LIN_description_file;
LIN_protocol_version = "2.1";
LIN_language_version = "2.1";
LIN_speed = 19.2 kbps;

Nodes {
  Master: BCM, 10 ms, 0.1 ms ;
  Slave: DHL, HFA, LIN尾燈, PWM, RLN, RLS, CEM, RLN ;
}

Signals {
  WiprReq: 3, 10, RLS, BCM ;
  PosnLightReq: 1, 0, RLS, BCM ;
  LowBeamReq: 1, 0, RLS, BCM ;
  RLS_RespErr: 1, 0, RLS, BCM ;
  LightSnsrFailSts: 1, 0, RLS, BCM ;
  RainSnsrFailSts: 1, 0, RLS, BCM ;
  TempFailSts: 1, 0, RLS, BCM ;
  InitnFailSts: 1, 0, RLS, BCM ;
  VoltFailSts: 1, 0, RLS, BCM ;
  CloseSRReq: 1, 0, RLS, BCM ;
  VehTypFailrSts: 1, 0, RLS, BCM ;
  DHL_DoorHndlReq: 2, 0, DHL, BCM ;
  DHL_LockSnsrErr: 1, 0, DHL, BCM ;
  DHL_UnlockSnsrErr: 1, 0, DHL, BCM ;
  HFA_OperReq: 2, 0, HFA, BCM ;
  HFA_RespErr: 2, 0, HFA, BCM ;
  HFA_HWErr: 1, 0, HFA, BCM ;
  CentralCtrlLockSwtErrSts: 1, 0, PWM, BCM ;
  PowerCutSwtErrSts: 1, 0, PWM, BCM ;
  CentralCtrlLockSwt: 1, 0, PWM, BCM ;
  PowerCutSwt: 1, 0, PWM, BCM ;
  MirrFoldSwt: 1, 0, PWM, BCM ;
  MirrFold_LSeldSwtErrSts: 1, 0, PWM, BCM ;
  MirrFold_RSeldSwtErrSts: 1, 0, PWM, BCM ;
  Mirr_Swt_Cmd: 4, 0, PWM, BCM ;
  Mirr_Swt_CmdErrSts: 1, 0, PWM, BCM ;
  RFLBrkLmpSts: 1, 0, LIN尾燈, CEM ;
  LBrkLmpFailSts_RLN: 1, 0, RLN, BCM ;
  RBrkLmpFailSts_RLN: 1, 0, RLN, BCM ;
  HiPosnBrkBeamFailSts_RLN: 1, 0, RLN, BCM ;
  LPosnBeamFailSts_RLN: 1, 0, RLN, BCM ;
  RPosnBeamFailSts_RLN: 1, 0, RLN, BCM ;
  LTurnBeamFailSts_RLN: 1, 0, RLN, BCM ;
  RTurnBeamFailSts_RLN: 1, 0, RLN, BCM ;
  LRvrsBeamFailSts_RLN: 1, 0, RLN, BCM ;
  RRvrsBeamFailSts_RLN: 1, 0, RLN, BCM ;
  RTurnLmpWorkCmd_RLN: 1, 0, BCM, RLN ;
  LTurnLmpWorkCmd_RLN: 1, 0, BCM, RLN ;
  RRPosnLmpWorkCmd_RLN: 1, 0, BCM, RLN ;
  LRPosnLmpWorkCmd_RLN: 1, 0, BCM, RLN ;
  ReversLampWorkCmd_RLN: 1, 0, BCM, RLN ;
  BrkLmpWorkCmd_RLN: 1, 0, BCM, RLN ;
}

Frames {
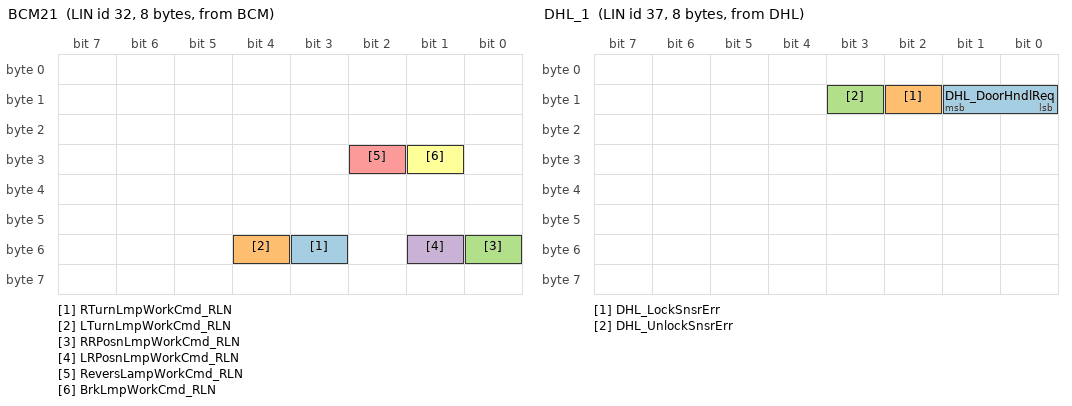
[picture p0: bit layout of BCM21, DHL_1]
  BCM21: 32, BCM, 8 {
    RTurnLmpWorkCmd_RLN, 51 ;
    LTurnLmpWorkCmd_RLN, 52 ;
    RRPosnLmpWorkCmd_RLN, 48 ;
    LRPosnLmpWorkCmd_RLN, 49 ;
    ReversLampWorkCmd_RLN, 26 ;
    BrkLmpWorkCmd_RLN, 25 ;
  }
  DHL_1: 37, DHL, 8 {
    DHL_DoorHndlReq, 8 ;
    DHL_LockSnsrErr, 10 ;
    DHL_UnlockSnsrErr, 11 ;
  }
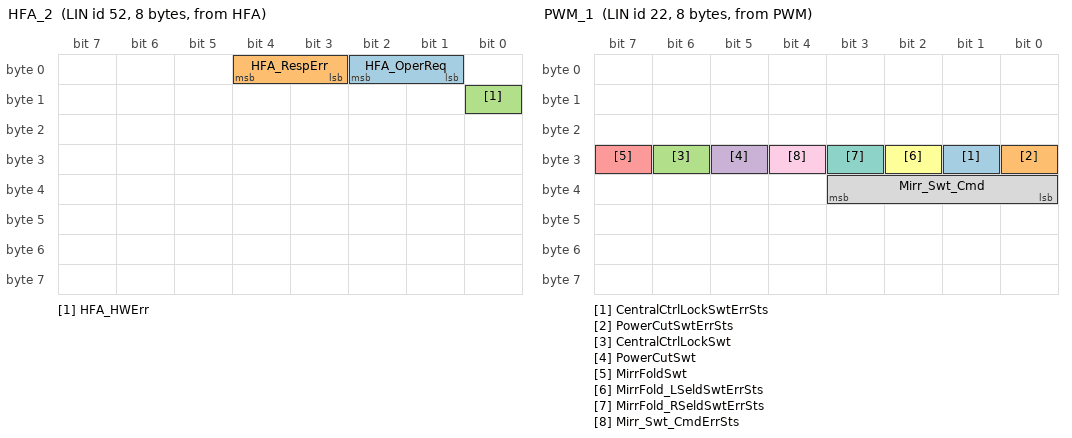
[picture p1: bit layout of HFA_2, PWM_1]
  HFA_2: 52, HFA, 8 {
    HFA_OperReq, 1 ;
    HFA_RespErr, 3 ;
    HFA_HWErr, 8 ;
  }
  PWM_1: 22, PWM, 8 {
    CentralCtrlLockSwtErrSts, 25 ;
    PowerCutSwtErrSts, 24 ;
    CentralCtrlLockSwt, 30 ;
    PowerCutSwt, 29 ;
    MirrFoldSwt, 31 ;
    MirrFold_LSeldSwtErrSts, 26 ;
    MirrFold_RSeldSwtErrSts, 27 ;
    Mirr_Swt_Cmd, 32 ;
    Mirr_Swt_CmdErrSts, 28 ;
  }
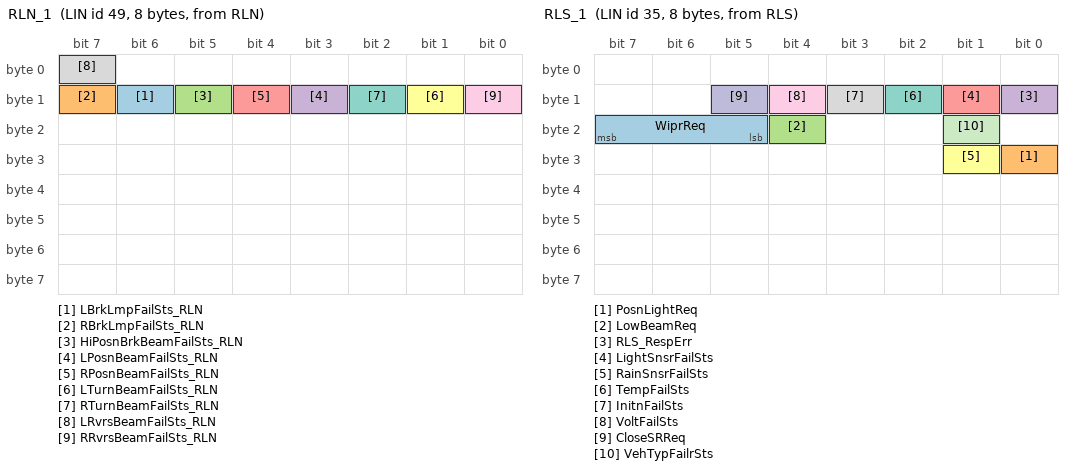
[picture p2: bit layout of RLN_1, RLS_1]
  RLN_1: 49, RLN, 8 {
    LBrkLmpFailSts_RLN, 14 ;
    RBrkLmpFailSts_RLN, 15 ;
    HiPosnBrkBeamFailSts_RLN, 13 ;
    LPosnBeamFailSts_RLN, 11 ;
    RPosnBeamFailSts_RLN, 12 ;
    LTurnBeamFailSts_RLN, 9 ;
    RTurnBeamFailSts_RLN, 10 ;
    LRvrsBeamFailSts_RLN, 7 ;
    RRvrsBeamFailSts_RLN, 8 ;
  }
  RLS_1: 35, RLS, 8 {
    WiprReq, 21 ;
    PosnLightReq, 24 ;
    LowBeamReq, 20 ;
    RLS_RespErr, 8 ;
    LightSnsrFailSts, 9 ;
    RainSnsrFailSts, 25 ;
    TempFailSts, 10 ;
    InitnFailSts, 11 ;
    VoltFailSts, 12 ;
    CloseSRReq, 13 ;
    VehTypFailrSts, 17 ;
  }
  TLM_1: 49, LIN尾燈, 8 {
    RFLBrkLmpSts, 28 ;
  }
}

Diagnostic_frame {
  MasterReq: 0x3c {
    MasterReqB0, 0 ;
    MasterReqB1, 8 ;
    MasterReqB2, 16 ;
    MasterReqB3, 24 ;
    MasterReqB4, 32 ;
    MasterReqB5, 40 ;
    MasterReqB6, 48 ;
    MasterReqB7, 56 ;
  }
  SlaveResp: 0x3d {
    SlaveRespB0, 0 ;
    SlaveRespB1, 8 ;
    SlaveRespB2, 16 ;
    SlaveRespB3, 24 ;
    SlaveRespB4, 32 ;
    SlaveRespB5, 40 ;
    SlaveRespB6, 48 ;
    SlaveRespB7, 56 ;
  }
}

Node_attributes {
  DHL {
    LIN_protocol = "2.1"
    configured_NAD = 0
    initial_NAD = 0x0
    product_id = 0xFFFF, 0xFFFF, 0xFFF
    P2_min = 50 ms
    ST_min = 0 ms
    N_As_timeout = 1000 ms
    N_Cr_timeout = 1000 ms
    configurable_frames {
      DHL_1 ;
    }
  }
  HFA {
    LIN_protocol = "2.1"
    configured_NAD = 0
    initial_NAD = 0x0
    product_id = 0xFFFF, 0xFFFF, 0xFFF
    P2_min = 50 ms
    ST_min = 0 ms
    N_As_timeout = 1000 ms
    N_Cr_timeout = 1000 ms
    configurable_frames {
      HFA_2 ;
    }
  }
  LIN尾燈 {
    LIN_protocol = "2.1"
    configured_NAD = 0
    initial_NAD = 0x0
    product_id = 0xFFFF, 0xFFFF, 0xFFF
    P2_min = 50 ms
    ST_min = 0 ms
    N_As_timeout = 1000 ms
    N_Cr_timeout = 1000 ms
    configurable_frames {
      TLM_1 ;
    }
  }
  PWM {
    LIN_protocol = "2.1"
    configured_NAD = 0
    initial_NAD = 0x0
    product_id = 0xFFFF, 0xFFFF, 0xFFF
    P2_min = 50 ms
    ST_min = 0 ms
    N_As_timeout = 1000 ms
    N_Cr_timeout = 1000 ms
    configurable_frames {
      PWM_1 ;
    }
  }
  RLN {
    LIN_protocol = "2.1"
    configured_NAD = 0
    initial_NAD = 0x0
    product_id = 0xFFFF, 0xFFFF, 0xFFF
    P2_min = 50 ms
    ST_min = 0 ms
    N_As_timeout = 1000 ms
    N_Cr_timeout = 1000 ms
    configurable_frames {
      BCM21 ;
      RLN_1 ;
    }
  }
  RLS {
    LIN_protocol = "2.1"
    configured_NAD = 0
    initial_NAD = 0x0
    product_id = 0xFFFF, 0xFFFF, 0xFFF
    P2_min = 50 ms
    ST_min = 0 ms
    N_As_timeout = 1000 ms
    N_Cr_timeout = 1000 ms
    configurable_frames {
      RLS_1 ;
    }
  }
  CEM {
    LIN_protocol = "2.1"
    configured_NAD = 0
    initial_NAD = 0x0
    product_id = 0xFFFF, 0xFFFF, 0xFFF
    P2_min = 50 ms
    ST_min = 0 ms
    N_As_timeout = 1000 ms
    N_Cr_timeout = 1000 ms
    configurable_frames {
      TLM_1 ;
    }
  }
  RLN {
    LIN_protocol = "2.1"
    configured_NAD = 0
    initial_NAD = 0x0
    product_id = 0xFFFF, 0xFFFF, 0xFFF
    P2_min = 50 ms
    ST_min = 0 ms
    N_As_timeout = 1000 ms
    N_Cr_timeout = 1000 ms
    configurable_frames {
      BCM21 ;
      RLN_1 ;
    }
  }
  }

Schedule_tables {
 Table1 {
    RLS_1 delay 10 ms ;
    DHL_1 delay 10 ms ;
    HFA_2 delay 10 ms ;
    PWM_1 delay 10 ms ;
    RLN_1 delay 10 ms ;
    BCM21 delay 10 ms ;
    nan delay nan ms ;
    nan delay nan ms ;
    nan delay nan ms ;
    nan delay nan ms ;
    nan delay nan ms ;
    nan delay nan ms ;
    Message delay Delay[ms] ms ;
    DHL_1 delay 15 ms ;
    BCM_11 delay 15 ms ;
    BCM_13 delay 15 ms ;
    HFA_2 delay 15 ms ;
    nan delay nan ms ;
    nan delay nan ms ;
    Message delay Delay[ms] ms ;
    EBS1 delay 15 ms ;
    EBS2 delay 15 ms ;
    EBS3 delay 15 ms ;
    EBS4 delay 15 ms ;
    nan delay nan ms ;
    nan delay nan ms ;
    nan delay nan ms ;
    Message delay Delay[ms] ms ;
    ALCM_1 delay 10 ms ;
    nan delay nan ms ;
    nan delay nan ms ;
    nan delay nan ms ;
    Message delay Delay[ms] ms ;
    BCM_91 delay 10 ms ;
    nan delay nan ms ;
    nan delay nan ms ;
    nan delay nan ms ;
    Message delay Delay[ms] ms ;
    DDCM1 delay 15 ms ;
    PWM_1 delay 15 ms ;
  }
}
